# AM13E23019 register map
Vendor: Texas Instruments; File version: 1.0
CPU: CM33 r0p1, little endian, MPU, FPU, VTOR, 4 interrupt priority bits
Registers are 32-bit, read-write, reset 0x0 unless marked. A register's access mark holds for its fields unless they carry their own. Offsets are from the block's base; [hi:lo] are bit positions; lines under a group give offsets from that group; {n}, {i} and the like mark numbered series; 'fields as' and 'values as' point back to an identical list.

## NVMNW — NVMNW module
Base 0x40042000
0x480 CPU_CONNECT_0 — CPU Connect
  [1] CPUSS0_CONN — CPUSS0 connect bit.
    0=UNCONNECTED (The CPU is not connected.); 1=CONNECTED (The CPU is connected.)
0x1020 IIDX ro — Interrupt Index Register
  [0] STAT — Indicates which interrupt has fired. 0x0 means no event pending. The priority order is fixed. On each read, only one interrupt is indicated. On a read, the current interrupt (highest priority) is automatically cleared by the hardware and the corresponding interrupt flags in the RIS and MIS are cleared as well. After a read from the CPU (not from the debug interface), the register must be updated with the next highest priority interrupt.
    0=NO_INTR (No Interrupt Pending); 1=DONE (DONE Interrupt Pending)
0x1028 IMASK — Interrupt Mask Register
  [0] DONE — Interrupt mask for DONE: 0: Interrupt is disabled in MIS register 1: Interrupt is enabled in MIS register
    0=DISABLED (Interrupt is masked out); 1=ENABLED (Interrupt will request an interrupt service routine and corresponding bit in [IPSTANDARD.MIS] will be set)
0x1030 RIS ro — Raw Interrupt Status Register
  [0] DONE — Flash wrapper operation completed. This interrupt bit is set by firmware or the corresponding bit in the ISET register. It is cleared by the corresponding bit in in the ICLR register or reading the IIDX register when this interrupt is the highest priority.
    0=CLR (Interrupt did not occur); 1=SET (Interrupt occurred)
0x1038 MIS ro — Masked Interrupt Status Register
  [0] DONE — Flash wrapper operation completed. This masked interrupt bit reflects the bitwise AND of the corresponding RIS and IMASK bits.
    0=CLR (Masked interrupt did not occur); 1=SET (Masked interrupt occurred)
0x1040 ISET — Interrupt Set Register
  [0] DONE — 0: No effect 1: Set the DONE interrupt in the RIS register
    0=NO_EFFECT (Writing a 0 has no effect); 1=SET (Set [IPSTANDARD.RIS] bit)
0x1048 ICLR — Interrupt Clear Register
  [0] DONE — 0: No effect 1: Clear the DONE interrupt in the RIS register
    0=NO_EFFECT (Writing a 0 has no effect); 1=CLR (Clear [IPSTANDARD.RIS] bit)
0x1100 CMDEXEC — Command Execute Register
  [0] VAL — Command Execute value Initiates execution of the command specified in the CMDTYPE register.
    0=NOEXECUTE (Command will not execute or is not executing in flash wrapper); 1=EXECUTE (Command will execute or is executing in flash wrapper)
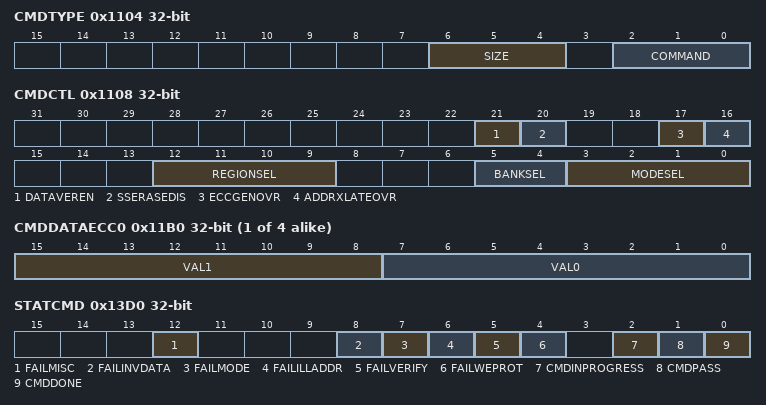
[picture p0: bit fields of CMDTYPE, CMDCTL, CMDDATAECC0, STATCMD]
0x1104 CMDTYPE — Command Type Register
  [6:4] SIZE — Command size
    0=ONEWORD (Operate on 1 flash word); 1=TWOWORD (Operate on 2 flash words); 2=FOURWORD (Operate on 4 flash words); 3=EIGHTWORD (Operate on 8 flash words); 4=SECTOR (Operate on a flash sector); 5=BANK (Operate on an entire flash bank)
  [2:0] COMMAND — Command type
    0=NOOP (No Operation); 1=PROGRAM; 2=ERASE; 3=READVERIFY__SECRET_ENUM (ReadVerify - Perform a standalone ReadVerify operation.); 4=MODECHANGE (Mode Change - Perform a mode change only, no other operation.); 5=CLEARSTATUS (Clear Status - Clear status bits in FW_SMSTAT only.); 6=BLANKVERIFY (Blank Verify - Check whether a flash word is in the erased state. This command may only be used with CMDTYPE.SIZE = ONEWORD)
0x1108 CMDCTL — Command Control Register
  [21] DATAVEREN — Enable invalid data verify. This checks for 0->1 transitions in the memory when a program operation is initiated. If such a transition is found, the program will fail with an error without executing the program.
    0=DISABLE; 1=ENABLE
  [20] SSERASEDIS — Disable Stair-Step Erase. If set, the default VHV trim voltage setting will be used for all erase pulses. By default, this bit is reset, meaning that the VHV voltage will be stepped during successive erase pulses. The step count, step voltage, begin and end voltages are all hard-wired.
    0=ENABLE; 1=DISABLE
  [17] ECCGENOVR — Override hardware generation of ECC data for program. Use data written to CMDDATAECC*.
    0=NOOVERRIDE (Do not override); 1=OVERRIDE
  [16] ADDRXLATEOVR — Override hardware address translation of address in CMDADDR from a system address to a bank address and bank ID. Use data written to CMDADDR directly as the bank address. Use the value written to CMDCTL.BANKSEL directly as the bank ID. Use the value written to CMDCTL.REGIONSEL directly as the region ID.
    0=NOOVERRIDE (Do not override); 1=OVERRIDE
  [12:9] REGIONSEL — Bank Region A specific region ID can be written to this field to indicate to which region an operation is to be applied if CMDCTL.ADDRXLATEOVR is set.
    1=MAIN (Main Region); 2=NONMAIN (Non-Main Region); 4=TRIM (Trim Region); 8=ENGR (Engr Region)
  [5:4] BANKSEL — Bank Select A specific Bank ID can be written to this field to indicate to which bank an operation is to be applied if CMDCTL.ADDRXLATEOVR is set.
    1=BANK0; 2=BANK1; 4=BANK2; 8=BANK3; 16=BANK4
  [3:0] MODESEL — Mode This field is only used for the Mode Change command type. Otherwise, bank and pump modes are set automaticlly through the NW hardware.
    0=READ (Read Mode); 2=RDMARG0 (Read Margin 0 Mode); 4=RDMARG1 (Read Margin 1 Mode); 6=RDMARG0B (Read Margin 0B Mode); 7=RDMARG1B (Read Margin 1B Mode); 9=PGMVER (Program Verify Mode); 10=PGMSW (Program Single Word); 11=ERASEVER (Erase Verify Mode); 12=ERASESECT (Erase Sector); 14=PGMMW (Program Multiple Word); 15=ERASEBNK (Erase Bank)
0x1120 CMDADDR — Command Address Register
  [31:0] VAL — Address value
    0=MINIMUM (Minimum value of [VAL]); 0xFFFFFFFF=MAXIMUM (Maximum value of [VAL])
0x1124 CMDBYTEN — Command Program Byte Enable Register
  [17:0] VAL — Command Byte Enable value. A 1-bit per flash word byte value is placed in this register.
    0=MINIMUM (Minimum value of [VAL]); 0x3FFFF=MAXIMUM (Maximum value of [VAL])
0x112C CMDDATAINDEX — Command Data Index Register
  [1:0] VAL — Data register index
    0=MINIMUM (Minimum value of [VAL]); 7=MAXIMUM (Maximum value of [VAL])
{0x1130+4i} CMDDATA{i} (i=0..2) — Command Data Register {i}
  [31:0] VAL — A 32-bit data value is placed in this field.
    values as CMDADDR.VAL
0x113C CMDDATA3 — Command Data Register Bits 127:96
  fields as CMDDATA0
0x1140 CMDDATA4 — Command Data Register 4
  [31:0] VAL — A 32-bit data value is placed in this field. T
    values as CMDADDR.VAL
{0x1130+4i} CMDDATA{i} (i=5..15) — Command Data Register {i}
  fields as CMDDATA0
{0x11B0+4i} CMDDATAECC{i} (i=0..3) — Command Data Register ECC {i}
  [15:8] VAL1 — ECC data for bits 127:64 of the data is placed here.
    0=MINIMUM (Minimum value); 255=MAXIMUM (Maximum value)
  [7:0] VAL0 — ECC data for bits 63:0 of the data is placed here.
    0=MINIMUM (Minimum value); 255=MAXIMUM (Maximum value)
0x11D0 CMDWEPROTA — Command Write Erase Protect A Register
  [31:0] VAL — Each bit protects 1 sector. bit [0]: When 1, sector 0 of the flash memory will be protected from program and erase. bit [1]: When 1, sector 1 of the flash memory will be protected from program and erase. : : bit [31]: When 1, sector 31 of the flash memory will be protected from program and erase.
    values as CMDADDR.VAL
0x11D4 CMDWEPROTB — Command Write Erase Protect B Register
  [11:0] VAL — Each bit protects a group of 8 sectors. When a bit is 1, the associated 8 sectors in the flash will be protected from program and erase. A maximum of 256 sectors can be protected with this register.
    values as CMDADDR.VAL
0x1210 CMDWEPROTNM — Command Write Erase Protect Non-Main Register
  [1:0] VAL — Each bit protects 1 sector. bit [0]: When 1, sector 0 of the non-main region will be protected from program and erase. bit [1]: When 1, sector 1 of the non-main region will be protected from program and erase. : : bit [31]: When 1, sector 31 of the non-main will be protected from program and erase.
    values as CMDADDR.VAL
0x13D0 STATCMD ro — Command Status Register
  [12] FAILMISC — Command failed due to error other than write/erase protect violation or verify error. This is an extra bit in case a new failure mechanism is added which requires a status bit.
    0=STATNOFAIL (No Fail); 1=STATFAIL (Fail)
  [8] FAILINVDATA — Program command failed because an attempt was made to program a stored 0 value to a 1.
    0=STATNOFAIL (No Fail); 1=STATFAIL (Fail)
  [7] FAILMODE — Command failed because a bank has been set to a mode other than READ. Program and Erase commands cannot be initiated unless all banks are in READ mode.
    0=STATNOFAIL (No Fail); 1=STATFAIL (Fail)
  [6] FAILILLADDR — Command failed due to the use of an illegal address
    0=STATNOFAIL (No Fail); 1=STATFAIL (Fail)
  [5] FAILVERIFY — Command failed due to verify error
    0=STATNOFAIL (No Fail); 1=STATFAIL (Fail)
  [4] FAILWEPROT — Command failed due to Write/Erase Protect Sector Violation
    0=STATNOFAIL (No Fail); 1=STATFAIL (Fail)
  [2] CMDINPROGRESS — Command In Progress
    0=STATCOMPLETE (Complete); 1=STATINPROGRESS (In Progress)
  [1] CMDPASS — Command Pass - valid when CMD_DONE field is 1
    0=STATFAIL (Fail); 1=STATPASS (Pass)
  [0] CMDDONE — Command Done
    0=STATNOTDONE (Not Done); 1=STATDONE (Done)
0x13D8 STATPCNT ro — Pulse Count Status Register
  [11:0] PULSECNT — Current Pulse Counter Value
    0=MINIMUM (Minimum value); 0xFFF=MAXIMUM (Maximum value)
0x1500 LMGMT_DFT_ATONLY group
